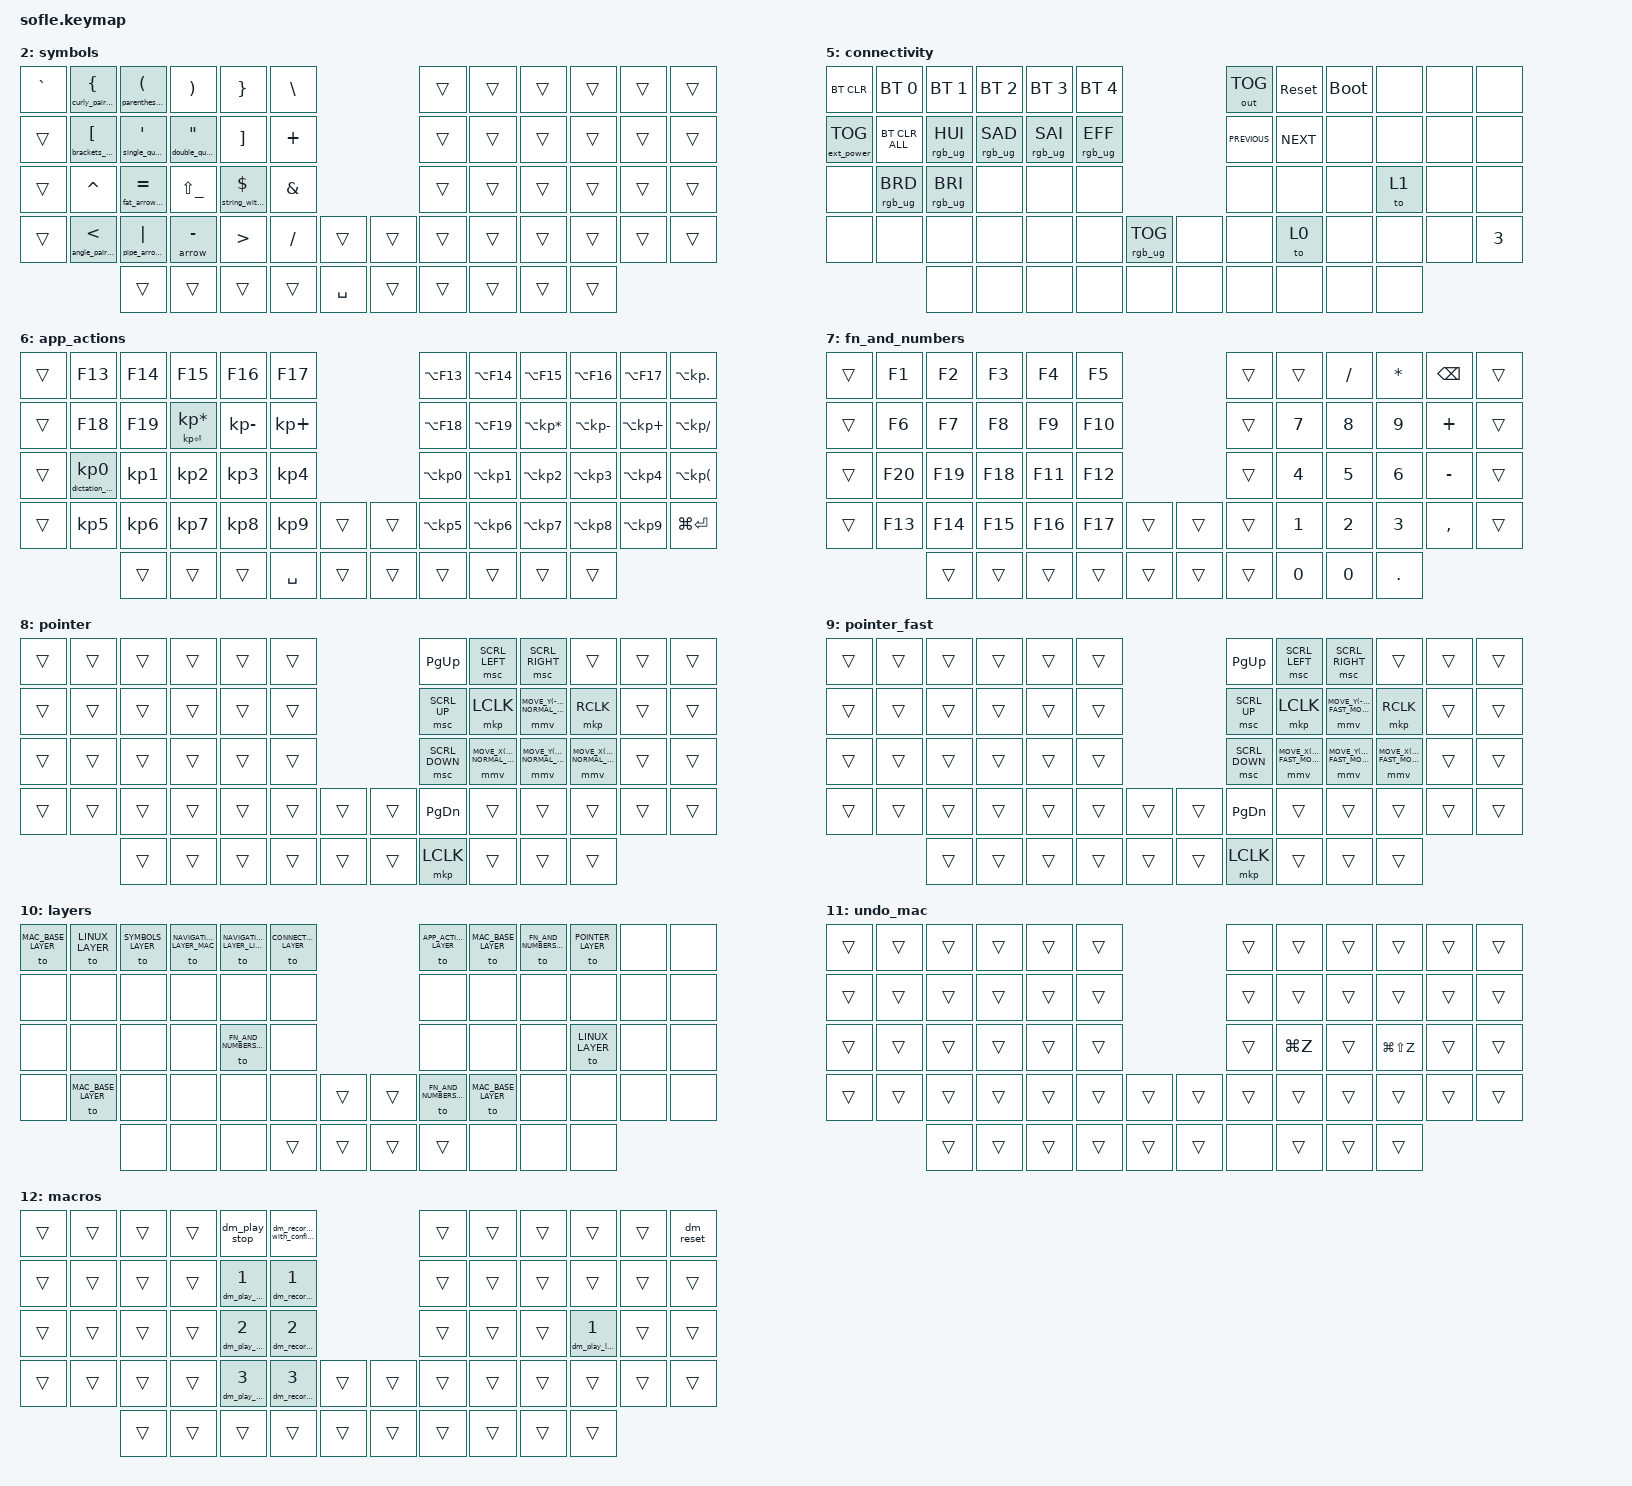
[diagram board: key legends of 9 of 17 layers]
/*
 * Copyright (c) 2020 The ZMK Contributors
 *
 * SPDX-License-Identifier: MIT
 */

#define ZMK_POINTING_DEFAULT_MOVE_VAL 1000  // default: 600
#define ZMK_POINTING_DEFAULT_SCRL_VAL 10    // default: 10
#define ZMK_POINTING_SLOW_MOVE_VAL 500
#define ZMK_POINTING_NORMAL_MOVE_VAL 1000
#define ZMK_POINTING_FAST_MOVE_VAL 3000

#include <behaviors.dtsi>
#include <dt-bindings/zmk/bt.h>
#include <dt-bindings/zmk/ext_power.h>
#include <dt-bindings/zmk/keys.h>
#include <dt-bindings/zmk/outputs.h>
#include <dt-bindings/zmk/pointing.h>
#include <dt-bindings/zmk/rgb.h>

#define OUTPUT_SOURCE_KEYCODE_STATE_CHANGE 3
#define MAC_BASE_LAYER 0
#define LINUX_LAYER 1
#define SYMBOLS_LAYER 2
#define NAVIGATION_LAYER_MAC 3
#define NAVIGATION_LAYER_LINUX 4
#define CONNECTIVITY_LAYER 5
#define APP_ACTIONS_LAYER 6
#define FN_AND_NUMBERS_LAYER 7
#define POINTER_LAYER 8
#define POINTER_FAST_LAYER 9
#define LAYERS_LAYER 10
#define UNDO_MAC_LAYER 11
#define MACROS_LAYER 12
#define APP_SWITCH_LAYER_LNX 13
#define WINDOW_SWITCH_LAYER_LNX 14
#define APP_SWITCH_LAYER_MAC 15
#define WINDOW_SWITCH_LAYER_MAC 16
#define SWITCH_COMBOS_TIMEOUT_MS 70
#define SWITCH_COMBOS_REQUIRE_PRIOR_IDLE_MS 400
#define STAGED_HOLD_TIMEOUT_MS 2000
#define STAGED_HOLD_WORD_STEP_MS 100

&left_encoder { status = "disabled"; };

&right_encoder {
    status = "ok";
    steps = <60>;
};

&sensors { triggers-per-rotation = <30>; };

/ {
    behaviors {
        backspace_words_mac: backspace_words_mac {
            compatible = "zmk,behavior-interval-repeat";
            #binding-cells = <0>;
            interval-ms = <STAGED_HOLD_WORD_STEP_MS>;
            bindings = <&kp LA(BACKSPACE)>;
        };

        backspace_staged_hold_mac: backspace_staged_hold_mac {
            compatible = "zmk,behavior-staged-hold";
            #binding-cells = <0>;
            timeout-ms = <STAGED_HOLD_TIMEOUT_MS>;
            on-press-bindings = <&kp BACKSPACE>;
            after-timeout-bindings = <&backspace_words_mac>;
        };

        left_staged_hold_mac: left_staged_hold_mac {
            compatible = "zmk,behavior-staged-hold";
            #binding-cells = <0>;
            timeout-ms = <STAGED_HOLD_TIMEOUT_MS>;
            on-press-bindings = <&kp LEFT>;
            after-timeout-bindings = <&kp LA(LEFT)>;
        };

        right_staged_hold_mac: right_staged_hold_mac {
            compatible = "zmk,behavior-staged-hold";
            #binding-cells = <0>;
            timeout-ms = <STAGED_HOLD_TIMEOUT_MS>;
            on-press-bindings = <&kp RIGHT>;
            after-timeout-bindings = <&kp LA(RIGHT)>;
        };

        backspace_words_lnx: backspace_words_lnx {
            compatible = "zmk,behavior-interval-repeat";
            #binding-cells = <0>;
            interval-ms = <STAGED_HOLD_WORD_STEP_MS>;
            bindings = <&kp LC(BACKSPACE)>;
        };

        backspace_staged_hold_lnx: backspace_staged_hold_lnx {
            compatible = "zmk,behavior-staged-hold";
            #binding-cells = <0>;
            timeout-ms = <STAGED_HOLD_TIMEOUT_MS>;
            on-press-bindings = <&kp BACKSPACE>;
            after-timeout-bindings = <&backspace_words_lnx>;
        };

        left_words_lnx: left_words_lnx {
            compatible = "zmk,behavior-interval-repeat";
            #binding-cells = <0>;
            interval-ms = <STAGED_HOLD_WORD_STEP_MS>;
            bindings = <&kp LC(LEFT)>;
        };

        left_staged_hold_lnx: left_staged_hold_lnx {
            compatible = "zmk,behavior-staged-hold";
            #binding-cells = <0>;
            timeout-ms = <STAGED_HOLD_TIMEOUT_MS>;
            on-press-bindings = <&kp LEFT>;
            after-timeout-bindings = <&left_words_lnx>;
        };

        right_words_lnx: right_words_lnx {
            compatible = "zmk,behavior-interval-repeat";
            #binding-cells = <0>;
            interval-ms = <STAGED_HOLD_WORD_STEP_MS>;
            bindings = <&kp LC(RIGHT)>;
        };

        right_staged_hold_lnx: right_staged_hold_lnx {
            compatible = "zmk,behavior-staged-hold";
            #binding-cells = <0>;
            timeout-ms = <STAGED_HOLD_TIMEOUT_MS>;
            on-press-bindings = <&kp RIGHT>;
            after-timeout-bindings = <&right_words_lnx>;
        };

        double_space_to_enter: double_space_to_enter {
            compatible = "zmk,behavior-tap-dance";
            #binding-cells = <0>;
            bindings = <&lt SYMBOLS_LAYER SPACE>, <&kp ENTER>;
        };

        gresc_ctrl: gresc_ctrl {
            compatible = "zmk,behavior-mod-morph";
            bindings = <&kp ESCAPE>, <&kp GRAVE>;

            #binding-cells = <0>;
            mods = <(MOD_LCTL|MOD_LGUI|MOD_LSFT|MOD_LALT)>;
        };

        dot_arrow: dot_arrow {
            compatible = "zmk,behavior-hold-tap";
            bindings = <&arrow>, <&kp>;

            #binding-cells = <2>;
            tapping-term-ms = <200>;
            flavor = "tap-preferred";
        };

        delayed_tap_hold_one: delayed_tap_hold_one {
            compatible = "zmk,behavior-hold-tap";
            bindings = <&kp>, <&kp>;

            #binding-cells = <2>;
            tapping-term-ms = <300>;
            flavor = "tap-preferred";
            require-prior-idle-ms = <200>;
        };

        hold_on_tab_mt: hold_on_tab_mt {
            compatible = "zmk,behavior-hold-tap";
            bindings = <&mt>, <&kp>;

            #binding-cells = <2>;
            tapping-term-ms = <400>;
            flavor = "tap-preferred";
        };

        shift_caps: shift_caps {
            compatible = "zmk,behavior-tap-dance";
            #binding-cells = <0>;
            bindings = <&kp LEFT_SHIFT>, <&kp CAPSLOCK>;
        };

        only_hold: only_hold {
            compatible = "zmk,behavior-hold-tap";
            bindings = <&kp>, <&none>;

            #binding-cells = <2>;
            tapping-term-ms = <400>;
            flavor = "tap-preferred";
        };

        only_tap_none_hold: only_tap_none_hold {
            compatible = "zmk,behavior-hold-tap";
            bindings = <&none>, <&kp>;

            #binding-cells = <2>;
            tapping-term-ms = <200>;
        };

        paste_on_hold_once: paste_on_hold_once {
            compatible = "zmk,behavior-hold-tap";
            bindings = <&paste_once>, <&kp>;

            #binding-cells = <2>;
            flavor = "tap-preferred";
            tapping-term-ms = <150>;
        };

        monosnap_image_copy: monosnap_image_copy {
            compatible = "zmk,behavior-mod-morph";
            bindings = <&kp C>, <&kp LA(LG(C))>;

            #binding-cells = <0>;
            mods = <(MOD_LCTL|MOD_LGUI)>;
        };

        copy_stuff: copy_stuff {
            compatible = "zmk,behavior-hold-tap";
            bindings = <&kp>, <&monosnap_image_copy>;

            #binding-cells = <2>;
            tapping-term-ms = <400>;
            flavor = "tap-preferred";
        };

        enter_shift_enter: enter_shift_enter {
            compatible = "zmk,behavior-hold-tap";
            bindings = <&single_shift_enter>, <&kp>;

            #binding-cells = <2>;
            tapping-term-ms = <200>;
            flavor = "tap-preferred";
        };

        to_layer_on_hold: to_layer_on_hold {
            compatible = "zmk,behavior-hold-tap";
            bindings = <&to>, <&kp>;

            #binding-cells = <2>;
            flavor = "tap-preferred";
            tapping-term-ms = <1000>;
        };

        copy_once_on_hold: copy_once_on_hold {
            compatible = "zmk,behavior-mod-morph";
            bindings = <&copy_once_on_hold_inner 0 C>, <&kp C>;

            #binding-cells = <0>;
            mods = <(MOD_LCTL|MOD_LGUI|MOD_LSFT|MOD_LALT)>;
            keep-mods = <(MOD_LCTL|MOD_LGUI|MOD_LSFT|MOD_LALT)>;
        };

        copy_once_on_hold_inner: copy_once_on_hold_inner {
            compatible = "zmk,behavior-hold-tap";
            bindings = <&copy_once>, <&kp>;

            #binding-cells = <2>;
            flavor = "tap-preferred";
            tapping-term-ms = <150>;
        };

        copy_once_on_hold_lnx: copy_once_on_hold_lnx {
            compatible = "zmk,behavior-mod-morph";
            bindings = <&copy_once_on_hold_inner_lnx 0 C>, <&kp C>;

            #binding-cells = <0>;
            mods = <(MOD_LCTL|MOD_LGUI|MOD_LSFT|MOD_LALT)>;
            keep-mods = <(MOD_LCTL|MOD_LGUI|MOD_LSFT|MOD_LALT)>;
        };

        copy_once_on_hold_inner_lnx: copy_once_on_hold_inner_lnx {
            compatible = "zmk,behavior-hold-tap";
            bindings = <&copy_once_lnx>, <&kp>;

            #binding-cells = <2>;
            flavor = "tap-preferred";
            tapping-term-ms = <150>;
        };

        ctrl_esc: ctrl_esc {
            compatible = "zmk,behavior-mod-morph";
            bindings = <&shift_esc>, <&kp LC(GRAVE)>;

            #binding-cells = <0>;
            mods = <(MOD_LCTL)>;
        };

        shift_esc: shift_esc {
            compatible = "zmk,behavior-mod-morph";
            bindings = <&esc_double_on_hold 0 0>, <&kp TILDE>;

            #binding-cells = <0>;
            mods = <(MOD_LSFT)>;
        };

        esc_double_on_hold: esc_double_on_hold {
            compatible = "zmk,behavior-hold-tap";
            bindings = <&esc_double_macro>, <&esc_tapdance>;

            #binding-cells = <2>;
            tapping-term-ms = <500>;
            flavor = "tap-preferred";
        };

        esc_tapdance: esc_tapdance {
            compatible = "zmk,behavior-tap-dance";
            #binding-cells = <0>;
            bindings =
                <&kp ESCAPE>,
                <&backtick_wrap>,
                <&triple_backtick>,
                <&triple_backtick_wrap_macro>;

            tapping-term-ms = <300>;
        };

        undo_once_on_hold: undo_once_on_hold {
            compatible = "zmk,behavior-hold-tap";
            bindings = <&undo_once>, <&kp>;

            #binding-cells = <2>;
            flavor = "tap-preferred";
            tapping-term-ms = <150>;
        };

        cut_once_on_hold: cut_once_on_hold {
            compatible = "zmk,behavior-hold-tap";
            bindings = <&cut_once>, <&kp>;

            #binding-cells = <2>;
            flavor = "tap-preferred";
            tapping-term-ms = <150>;
        };

        caps_lock_once_on_hold: caps_lock_once_on_hold {
            compatible = "zmk,behavior-hold-tap";
            bindings = <&caps_lock_once>, <&kp>;

            #binding-cells = <2>;
            flavor = "tap-preferred";
            tapping-term-ms = <200>;
        };

        paste_link_on_hold_once: paste_link_on_hold_once {
            compatible = "zmk,behavior-hold-tap";
            bindings = <&paste_link_macro>, <&kp>;

            #binding-cells = <2>;
            flavor = "tap-preferred";
            tapping-term-ms = <300>;
        };

        insert_bookmark_on_hold_once: insert_bookmark_on_hold_once {
            compatible = "zmk,behavior-hold-tap";
            bindings = <&insert_bookmark_macro>, <&kp>;

            #binding-cells = <2>;
            flavor = "tap-preferred";
            tapping-term-ms = <300>;
        };

        delayed_tap_once_on_hold: delayed_tap_once_on_hold {
            compatible = "zmk,behavior-hold-tap";
            bindings = <&key_once_macro>, <&kp>;

            #binding-cells = <2>;
            tapping-term-ms = <200>;
            flavor = "tap-preferred";
        };

        delayed_tap_once_haptic_on_hold: delayed_tap_once_haptic_on_hold {
            compatible = "zmk,behavior-hold-tap";
            bindings = <&key_once_haptic_macro>, <&kp>;

            #binding-cells = <2>;
            tapping-term-ms = <250>;
            flavor = "tap-preferred";
        };

        delayed_tap_once_haptic_on_hold_short: delayed_tap_once_haptic_on_hold_short {
            compatible = "zmk,behavior-hold-tap";
            bindings = <&key_once_haptic_macro>, <&kp>;

            #binding-cells = <2>;
            tapping-term-ms = <150>;
            flavor = "tap-preferred";
        };

        delayed_tap_once_haptic_on_hold_right: delayed_tap_once_haptic_on_hold_right {
            compatible = "zmk,behavior-hold-tap";
            bindings = <&key_once_haptic_macro_right>, <&kp>;

            #binding-cells = <2>;
            tapping-term-ms = <250>;
            flavor = "tap-preferred";
        };

        parenthesis_pair_on_hold: parenthesis_pair_on_hold {
            compatible = "zmk,behavior-hold-tap";
            bindings = <&parenthesis_pair_macro>, <&kp>;

            #binding-cells = <2>;
            tapping-term-ms = <200>;
            flavor = "tap-preferred";
        };

        brackets_pair_on_hold: brackets_pair_on_hold {
            compatible = "zmk,behavior-hold-tap";
            bindings = <&brackets_pair_macro>, <&kp>;

            #binding-cells = <2>;
            tapping-term-ms = <200>;
            flavor = "tap-preferred";
        };

        angle_pair_on_hold: angle_pair_on_hold {
            compatible = "zmk,behavior-hold-tap";
            bindings = <&angle_pair_macro>, <&kp>;

            #binding-cells = <2>;
            tapping-term-ms = <200>;
            flavor = "tap-preferred";
        };

        curly_pair_on_hold: curly_pair_on_hold {
            compatible = "zmk,behavior-hold-tap";
            bindings = <&curly_pair_macro>, <&kp>;

            #binding-cells = <2>;
            tapping-term-ms = <200>;
            flavor = "tap-preferred";
        };

        double_quote_pair_on_hold: double_quote_pair_on_hold {
            compatible = "zmk,behavior-hold-tap";
            bindings = <&double_quote_pair_macro>, <&kp>;

            #binding-cells = <2>;
            tapping-term-ms = <200>;
            flavor = "tap-preferred";
        };

        control_tapdance_to_suggestion: control_tapdance_to_suggestion {
            compatible = "zmk,behavior-tap-dance";
            label = "CONTROL_TAPDANCE_TO_SUGGESTION";
            #binding-cells = <0>;
            bindings = <&kp LCTRL>, <&kp LC(SPACE)>;

            tapping-term-ms = <250>;
        };

        long_delayed_tap_once_on_hold: long_delayed_tap_once_on_hold {
            compatible = "zmk,behavior-hold-tap";
            bindings = <&key_once_macro>, <&kp>;

            #binding-cells = <2>;
            tapping-term-ms = <500>;
            flavor = "tap-preferred";
            label = "LONG_DELAYED_TAP_ONCE_ON_HOLD";
        };

        fat_arrow_on_hold: fat_arrow_on_hold {
            compatible = "zmk,behavior-hold-tap";
            bindings = <&fat_arrow_macro>, <&kp>;

            #binding-cells = <2>;
            tapping-term-ms = <200>;
            flavor = "tap-preferred";
            label = "FAT_ARROW_ON_HOLD";
        };

        pipe_arrow_on_hold: pipe_arrow_on_hold {
            compatible = "zmk,behavior-hold-tap";
            bindings = <&pipe_arrow_macro>, <&kp>;

            #binding-cells = <2>;
            tapping-term-ms = <200>;
            flavor = "tap-preferred";
            label = "PIPE_ARROW_ON_HOLD";
        };

        string_with_var_on_hold: string_with_var_on_hold {
            compatible = "zmk,behavior-hold-tap";
            bindings = <&string_with_var_macro>, <&kp>;

            #binding-cells = <2>;
            tapping-term-ms = <200>;
            flavor = "tap-preferred";
            label = "STRING_WITH_VAR_ON_HOLD";
        };

        single_quote_pair_on_hold: single_quote_pair_on_hold {
            compatible = "zmk,behavior-hold-tap";
            bindings = <&single_quote_pair_macro>, <&kp>;

            #binding-cells = <2>;
            tapping-term-ms = <200>;
            flavor = "tap-preferred";
            label = "SINGLE_QUOTE_PAIR_ON_HOLD";
        };

        dictation_change_mode: dictation_change_mode {
            compatible = "zmk,behavior-mod-morph";
            label = "DICTATION_CHANGE_MODE";
            bindings =
                <&dictation_tap_hold LA(SPACE) LA(SPACE)>,
                <&kp LA(LG(SPACE))>;

            #binding-cells = <0>;
            mods = <(MOD_LGUI)>;
        };

        dictation_tap_hold: dictation_tap_hold {
            compatible = "zmk,behavior-hold-tap";
            bindings = <&dictation_alt_toggle_macro>, <&kp>;

            #binding-cells = <2>;
            tapping-term-ms = <200>;
            flavor = "tap-preferred";
        };

        dm_record: dm_record {
            compatible = "zmk,behavior-dm-record";
            #binding-cells = <1>;
        };

        dm_play: dm_play {
            compatible = "zmk,behavior-dm-play";
            #binding-cells = <1>;
        };

        dm_play_loop: dm_play_loop {
            compatible = "zmk,behavior-dm-play-loop";
            #binding-cells = <1>;
        };

        dm_record_stop: dm_record_stop {
            compatible = "zmk,behavior-dm-record-stop";
            #binding-cells = <0>;
        };

        dm_play_stop: dm_play_stop {
            compatible = "zmk,behavior-dm-play-stop";
            #binding-cells = <0>;
        };

        dm_reset: dm_reset {
            compatible = "zmk,behavior-dm-reset";
            #binding-cells = <0>;
        };

        dictation_home_row_on_hold: dictation_home_row_on_hold {
            compatible = "zmk,behavior-hold-tap";
            bindings = <&dictation_home_row>, <&kp>;

            #binding-cells = <2>;
            tapping-term-ms = <400>;
            flavor = "tap-preferred";
        };
    };

    macros {
        arrow: arrow {
            compatible = "zmk,behavior-macro";
            #binding-cells = <0>;
            bindings = <&kp MINUS &kp GT &kp LC(SPACE)>;
        };

        esc_double_macro: esc_double_macro {
            compatible = "zmk,behavior-macro";
            #binding-cells = <0>;
            bindings = <&kp ESCAPE &kp ESCAPE &haptic_long_press>;
        };

        paste_once: paste_plain {
            compatible = "zmk,behavior-macro";
            #binding-cells = <0>;
            bindings = <&kp LG(V) &haptic_long_press>;
        };

        single_shift_enter: single_shift_enter {
            compatible = "zmk,behavior-macro";
            #binding-cells = <0>;
            bindings = <&kp LS(ENTER)>;
        };

        copy_once: copy_once {
            compatible = "zmk,behavior-macro";
            #binding-cells = <0>;
            bindings = <&kp LG(C) &haptic_long_press>;
        };

        copy_once_lnx: copy_once_lnx {
            compatible = "zmk,behavior-macro";
            #binding-cells = <0>;
            bindings = <&kp LC(C) &haptic_long_press>;
        };

        triple_backtick: triple_backtick {
            compatible = "zmk,behavior-macro";
            #binding-cells = <0>;
            bindings = <&kp GRAVE &kp GRAVE &kp GRAVE>;
        };

        backtick_wrap: backtick_wrap {
            compatible = "zmk,behavior-macro";
            #binding-cells = <0>;
            bindings = <&kp LG(X) &kp GRAVE &kp GRAVE &kp LEFT_ARROW &kp LG(V)>;
        };

        undo_once: undo_once {
            compatible = "zmk,behavior-macro";
            #binding-cells = <0>;
            bindings =
                <&kp LG(Z) &haptic_long_press>,
                <&macro_press>,
                <&mo UNDO_MAC_LAYER>,
                <&macro_pause_for_release>,
                <&macro_release>,
                <&mo UNDO_MAC_LAYER>;
        };

        cut_once: cut_once {
            compatible = "zmk,behavior-macro";
            #binding-cells = <0>;
            bindings = <&kp LG(X) &haptic_long_press>;
        };

        caps_lock_once: caps_lock_once {
            compatible = "zmk,behavior-macro";
            #binding-cells = <0>;
            bindings = <&kp CAPSLOCK &haptic_long_press>;
        };

        paste_link_macro: paste_link_macro {
            compatible = "zmk,behavior-macro";
            #binding-cells = <0>;
            bindings =
                <&kp LG(K)>,
                <&macro_wait_time 200>,
                <&kp LG(V) &kp ENTER>;
        };

        insert_bookmark_macro: insert_bookmark {
            compatible = "zmk,behavior-macro";
            #binding-cells = <0>;
            bindings =
                <&kp LC(LA(I))>,
                <&macro_wait_time 200>,
                <&kp B &haptic_long_press>;
        };

        triple_backtick_wrap_macro: triple_backtick_wrap_macro {
            compatible = "zmk,behavior-macro";
            #binding-cells = <0>;
            bindings =
                <&kp GRAVE &kp GRAVE &kp GRAVE>,
                <&macro_wait_time 100>,
                <&kp LS(ENTER) &kp LG(V)>,
                <&macro_wait_time 15>,
                <&kp LS(ENTER) &kp GRAVE &kp GRAVE &kp GRAVE>;
        };

        docs_reset_format_macro: docs_reset_format_macro {
            compatible = "zmk,behavior-macro";
            #binding-cells = <0>;
            bindings = <&none>;
        };

        docs_wrap_text_macro: docs_wrap_text_macro {
            compatible = "zmk,behavior-macro";
            #binding-cells = <0>;
            bindings = <&kp LC(LA(O)) &kp W &kp W>;
        };

        key_once_macro: key_once_macro {
            compatible = "zmk,behavior-macro-one-param";
            #binding-cells = <1>;
            bindings = <&macro_param_1to1 &kp MACRO_PLACEHOLDER>;
        };

        key_once_haptic_macro: key_once_haptic_macro {
            compatible = "zmk,behavior-macro-one-param";
            #binding-cells = <1>;
            bindings = <&macro_param_1to1 &kp MACRO_PLACEHOLDER &haptic_long_press>;
        };

        key_once_haptic_macro_right: key_once_haptic_macro_right {
            compatible = "zmk,behavior-macro-one-param";
            #binding-cells = <1>;
            bindings = <&macro_param_1to1 &kp MACRO_PLACEHOLDER &haptic_long_press_right>;
        };

        parenthesis_pair_macro: parenthesis_pair_macro {
            compatible = "zmk,behavior-macro";
            #binding-cells = <0>;
            bindings = <&kp LPAR &kp RPAR &kp LEFT &haptic_long_press>;
        };

        brackets_pair_macro: brackets_pair_macro {
            compatible = "zmk,behavior-macro";
            #binding-cells = <0>;
            bindings = <&kp LEFT_BRACKET &kp RIGHT_BRACKET &kp LEFT &haptic_long_press>;
        };

        angle_pair_macro: angle_pair_macro {
            compatible = "zmk,behavior-macro";
            #binding-cells = <0>;
            bindings = <&kp LT &kp GT &kp LEFT &haptic_long_press>;
        };

        curly_pair_macro: curly_pair_macro {
            compatible = "zmk,behavior-macro";
            #binding-cells = <0>;
            bindings = <&kp LS(LBRC) &kp RBRC &kp LEFT &haptic_long_press>;
        };

        double_quote_pair_macro: double_quote_pair_macro {
            compatible = "zmk,behavior-macro";
            #binding-cells = <0>;
            bindings = <&kp DQT &kp DQT &kp LEFT &haptic_long_press>;
        };

        fat_arrow_macro: fat_arrow_macro {
            compatible = "zmk,behavior-macro";
            #binding-cells = <0>;
            bindings = <&kp KP_EQUAL &kp GREATER_THAN &haptic_long_press>;
            label = "FAT_ARROW_MACRO";
        };

        pipe_arrow_macro: pipe_arrow_macro {
            compatible = "zmk,behavior-macro";
            #binding-cells = <0>;
            bindings = <&kp PIPE &kp GREATER_THAN &haptic_long_press>;
            label = "PIPE_ARROW_MACRO";
        };

        string_with_var_macro: string_with_var_macro {
            compatible = "zmk,behavior-macro";
            #binding-cells = <0>;
            bindings = <&kp DOLLAR &kp LEFT_BRACE &kp RIGHT_BRACE &kp LEFT &haptic_long_press>;
            label = "STRING_WITH_VAR_MACRO";
        };

        single_quote_pair_macro: single_quote_pair_macro {
            compatible = "zmk,behavior-macro";
            #binding-cells = <0>;
            bindings = <&kp SQT &kp SQT &kp LEFT &haptic_long_press>;
            label = "SINGLE_QUOTE_PAIR_MACRO";
        };

        dictation_toggle_macro: dictation_toggle_macro {
            compatible = "zmk,behavior-macro";
            #binding-cells = <0>;
            bindings =
                <&kp LA(ESCAPE)>,
                <&macro_pause_for_release>,
                <&kp LA(ESCAPE)>;

            label = "DICTATION_TOGGLE_MACRO";
        };

        dictation_alt_toggle_macro: dictation_alt_toggle_macro {
            compatible = "zmk,behavior-macro";
            #binding-cells = <0>;
            bindings =
                <&kp LA(SPACE)>,
                <&macro_pause_for_release>,
                <&kp LA(SPACE)>;

            label = "DICTATION_ALT_TOGGLE_MACRO";
        };

        dm_record_with_confirmation: record_with_confirmation {
            compatible = "zmk,behavior-macro-one-param";
            #binding-cells = <1>;
            bindings = <&macro_param_1to1 &haptic_drv2605 MACRO_PLACEHOLDER &dm_record MACRO_PLACEHOLDER>;
        };

        dm_record_stop_with_confirmation: record_stop_with_confirmation {
            compatible = "zmk,behavior-macro";
            #binding-cells = <0>;
            bindings = <&dm_record_stop &haptic_drv2605 12>;
        };

        dm_play_with_confirmation: play_with_confirmation {
            compatible = "zmk,behavior-macro-one-param";
            #binding-cells = <1>;
            bindings =
                <&macro_param_1to1>,
                <&macro_wait_time 1000>,
                <&haptic_drv2605 MACRO_PLACEHOLDER &dm_play MACRO_PLACEHOLDER>;
        };

        dm_play_loop_with_confirmation: dm_play_loop_with_confirmation {
            compatible = "zmk,behavior-macro-one-param";
            #binding-cells = <1>;
            bindings =
                <&macro_param_1to1>,
                <&macro_wait_time 1000>,
                <&haptic_drv2605 MACRO_PLACEHOLDER &dm_play_loop MACRO_PLACEHOLDER>;
        };

        haptic_long_press: haptic_long_press {
            compatible = "zmk,behavior-macro";
            #binding-cells = <0>;
            bindings = <&haptic_drv2605 9>;
        };

        haptic_long_press_right: haptic_long_press_right {
            compatible = "zmk,behavior-macro";
            #binding-cells = <0>;
            bindings = <&haptic_drv2605_right 9>;
        };

        mouse_reset_position: mouse_reset_position {
            compatible = "zmk,behavior-macro";
            #binding-cells = <0>;
            bindings = <&mmv MOVE_Y(600) &mmv (MOVE_X(-600))>;
            label = "MOUSE_RESET_POSITION";
        };

        app_switch_start_lnx: app_switch_start_lnx {
            compatible = "zmk,behavior-macro";
            #binding-cells = <0>;
            bindings =
                <&macro_press>,
                <&mo APP_SWITCH_LAYER_LNX &kp LEFT_ALT>,
                <&macro_tap>,
                <&kp TAB>;
        };

        app_switch_start_mac: app_switch_start_mac {
            compatible = "zmk,behavior-macro";
            #binding-cells = <0>;
            bindings =
                <&macro_press>,
                <&mo APP_SWITCH_LAYER_MAC &kp LEFT_GUI>,
                <&macro_tap>,
                <&kp TAB>;
        };

        app_switch_confirm: app_switch_confirm {
            compatible = "zmk,behavior-macro";
            #binding-cells = <0>;
            bindings =
                <&macro_release>,
                <&kp LEFT_GUI &kp LEFT_ALT &mo APP_SWITCH_LAYER_MAC &mo APP_SWITCH_LAYER_LNX>,
                <&macro_tap>;
        };

        app_switch_cancel: app_switch_cancel {
            compatible = "zmk,behavior-macro";
            #binding-cells = <0>;
            bindings =
                <&macro_tap>,
                <&kp ESC>,
                <&macro_release>,
                <&kp LEFT_GUI &kp LEFT_ALT &mo APP_SWITCH_LAYER_MAC &mo APP_SWITCH_LAYER_LNX>;
        };

        window_switch_start_lnx: window_switch_start_lnx {
            compatible = "zmk,behavior-macro";
            #binding-cells = <0>;
            bindings =
                <&macro_press>,
                <&mo WINDOW_SWITCH_LAYER_LNX &kp LEFT_ALT>,
                <&macro_tap>,
                <&kp GRAVE>;
        };

        window_switch_start_mac: window_switch_start_mac {
            compatible = "zmk,behavior-macro";
            #binding-cells = <0>;
            bindings =
                <&macro_press>,
                <&mo WINDOW_SWITCH_LAYER_MAC &kp LEFT_ALT>,
                <&macro_tap>,
                <&kp GRAVE>;
        };

        window_switch_confirm: window_switch_confirm {
            compatible = "zmk,behavior-macro";
            #binding-cells = <0>;
            bindings =
                <&macro_release>,
                <&kp LEFT_ALT &mo WINDOW_SWITCH_LAYER_LNX &mo WINDOW_SWITCH_LAYER_MAC>,
                <&macro_tap>;
        };

        window_switch_cancel: window_switch_cancel {
            compatible = "zmk,behavior-macro";
            #binding-cells = <0>;
            bindings =
                <&macro_tap>,
                <&kp ESC>,
                <&macro_release>,
                <&kp LEFT_ALT &mo WINDOW_SWITCH_LAYER_LNX &mo WINDOW_SWITCH_LAYER_MAC>;
        };

        app_switch_to_window_switch_lnx: app_switch_to_window_switch_lnx {
            compatible = "zmk,behavior-macro";
            #binding-cells = <0>;
            bindings = <&app_switch_cancel &window_switch_start_lnx>;
        };

        app_switch_to_window_switch_mac: app_switch_to_window_switch_mac {
            compatible = "zmk,behavior-macro";
            #binding-cells = <0>;
            bindings = <&app_switch_cancel &window_switch_start_mac>;
        };

        window_switch_to_app_switch_lnx: window_switch_to_app_switch_lnx {
            compatible = "zmk,behavior-macro";
            #binding-cells = <0>;
            bindings = <&window_switch_cancel &app_switch_start_lnx>;
        };

        window_switch_to_app_switch_mac: window_switch_to_app_switch_mac {
            compatible = "zmk,behavior-macro";
            #binding-cells = <0>;
            bindings = <&window_switch_cancel &app_switch_start_mac>;
        };

        dictation_home_row: dictation_home_row {
            compatible = "zmk,behavior-macro";
            #binding-cells = <0>;
            bindings = <&kp LA(SPACE) &haptic_drv2605 13>;
        };
    };

    combos {
        compatible = "zmk,combos";

        to_pointer_layer {
            bindings = <&mo POINTER_LAYER>;
            key-positions = <28 27 26>;
            layers = <6>;
            timeout-ms = <1000>;
        };

        to_pointer_fast_layer {
            bindings = <&mo POINTER_FAST_LAYER>;
            key-positions = <16 14 15>;
            layers = <6>;
            timeout-ms = <1000>;
        };

        app_switch_lnx {
            bindings = <&app_switch_start_lnx>;
            key-positions = <28 27>;
            require-prior-idle-ms = <SWITCH_COMBOS_REQUIRE_PRIOR_IDLE_MS>;
            timeout-ms = <SWITCH_COMBOS_TIMEOUT_MS>;
            layers = <LINUX_LAYER>;
            slow-release;
        };

        app_switch_mac {
            bindings = <&app_switch_start_mac>;
            key-positions = <28 27>;
            require-prior-idle-ms = <SWITCH_COMBOS_REQUIRE_PRIOR_IDLE_MS>;
            timeout-ms = <SWITCH_COMBOS_TIMEOUT_MS>;
            layers = <MAC_BASE_LAYER>;
            slow-release;
        };

        app_switch_previous_fast_lnx {
            bindings = <&kp LA(TAB)>;
            key-positions = <26 27 28>;
            require-prior-idle-ms = <SWITCH_COMBOS_REQUIRE_PRIOR_IDLE_MS>;
            timeout-ms = <SWITCH_COMBOS_TIMEOUT_MS>;
            layers = <LINUX_LAYER>;
        };

        app_switch_previous_fast_mac {
            bindings = <&kp LG(TAB)>;
            key-positions = <26 27 28>;
            require-prior-idle-ms = <SWITCH_COMBOS_REQUIRE_PRIOR_IDLE_MS>;
            timeout-ms = <SWITCH_COMBOS_TIMEOUT_MS>;
            layers = <MAC_BASE_LAYER>;
        };

        app_switch_on_app_switch_layer_lnx {
            bindings = <&app_switch_cancel>;
            key-positions = <28 27>;
            require-prior-idle-ms = <SWITCH_COMBOS_REQUIRE_PRIOR_IDLE_MS>;
            timeout-ms = <SWITCH_COMBOS_TIMEOUT_MS>;
            layers = <APP_SWITCH_LAYER_LNX>;
            slow-release;
        };

        app_switch_on_app_switch_layer_mac {
            bindings = <&app_switch_cancel>;
            key-positions = <28 27>;
            require-prior-idle-ms = <SWITCH_COMBOS_REQUIRE_PRIOR_IDLE_MS>;
            timeout-ms = <SWITCH_COMBOS_TIMEOUT_MS>;
            layers = <APP_SWITCH_LAYER_MAC>;
            slow-release;
        };

        app_switch_on_window_switch_layer_lnx {
            bindings = <&window_switch_to_app_switch_lnx>;
            key-positions = <28 27>;
            require-prior-idle-ms = <SWITCH_COMBOS_REQUIRE_PRIOR_IDLE_MS>;
            timeout-ms = <SWITCH_COMBOS_TIMEOUT_MS>;
            layers = <WINDOW_SWITCH_LAYER_LNX>;
            slow-release;
        };

        app_switch_on_window_switch_layer_mac {
            bindings = <&window_switch_to_app_switch_mac>;
            key-positions = <28 27>;
            require-prior-idle-ms = <SWITCH_COMBOS_REQUIRE_PRIOR_IDLE_MS>;
            timeout-ms = <SWITCH_COMBOS_TIMEOUT_MS>;
            layers = <WINDOW_SWITCH_LAYER_MAC>;
            slow-release;
        };

        window_switch_lnx {
            bindings = <&window_switch_start_lnx>;
            key-positions = <15 28>;
            slow-release;
            require-prior-idle-ms = <SWITCH_COMBOS_REQUIRE_PRIOR_IDLE_MS>;
            timeout-ms = <SWITCH_COMBOS_TIMEOUT_MS>;
            layers = <LINUX_LAYER>;
        };

        window_switch_mac {
            bindings = <&window_switch_start_mac>;
            key-positions = <15 28>;
            slow-release;
            require-prior-idle-ms = <SWITCH_COMBOS_REQUIRE_PRIOR_IDLE_MS>;
            timeout-ms = <SWITCH_COMBOS_TIMEOUT_MS>;
            layers = <MAC_BASE_LAYER>;
        };

        window_switch_previous_fast_lnx {
            bindings = <&kp LA(GRAVE)>;
            key-positions = <14 15 16>;
            require-prior-idle-ms = <SWITCH_COMBOS_REQUIRE_PRIOR_IDLE_MS>;
            timeout-ms = <SWITCH_COMBOS_TIMEOUT_MS>;
            layers = <LINUX_LAYER>;
        };

        window_switch_previous_fast_mac {
            bindings = <&kp LA(GRAVE)>;
            key-positions = <14 15 16>;
            require-prior-idle-ms = <SWITCH_COMBOS_REQUIRE_PRIOR_IDLE_MS>;
            timeout-ms = <SWITCH_COMBOS_TIMEOUT_MS>;
            layers = <MAC_BASE_LAYER>;
        };

        window_switch_on_window_switch_layer_lnx {
            bindings = <&window_switch_cancel>;
            key-positions = <15 28>;
            require-prior-idle-ms = <SWITCH_COMBOS_REQUIRE_PRIOR_IDLE_MS>;
            timeout-ms = <SWITCH_COMBOS_TIMEOUT_MS>;
            layers = <WINDOW_SWITCH_LAYER_LNX>;
            slow-release;
        };

        window_switch_on_window_switch_layer_mac {
            bindings = <&window_switch_cancel>;
            key-positions = <15 28>;
            require-prior-idle-ms = <SWITCH_COMBOS_REQUIRE_PRIOR_IDLE_MS>;
            timeout-ms = <SWITCH_COMBOS_TIMEOUT_MS>;
            layers = <WINDOW_SWITCH_LAYER_MAC>;
            slow-release;
        };

        window_switch_on_app_switch_layer_lnx {
            bindings = <&app_switch_to_window_switch_lnx>;
            key-positions = <15 28>;
            require-prior-idle-ms = <SWITCH_COMBOS_REQUIRE_PRIOR_IDLE_MS>;
            timeout-ms = <SWITCH_COMBOS_TIMEOUT_MS>;
            layers = <APP_SWITCH_LAYER_LNX>;
            slow-release;
        };

        window_switch_on_app_switch_layer_mac {
            bindings = <&app_switch_to_window_switch_mac>;
            key-positions = <15 28>;
            require-prior-idle-ms = <SWITCH_COMBOS_REQUIRE_PRIOR_IDLE_MS>;
            timeout-ms = <SWITCH_COMBOS_TIMEOUT_MS>;
            layers = <APP_SWITCH_LAYER_MAC>;
            slow-release;
        };
    };

    keymap {
        compatible = "zmk,keymap";

        mac {
            display-name = "mac";
            bindings = <
&ctrl_esc                        &delayed_tap_once_on_hold F1 N1           &delayed_tap_once_on_hold F2 N2           &delayed_tap_once_on_hold F3 N3    &delayed_tap_once_on_hold F4 N4           &delayed_tap_once_on_hold F5 N5                                                                 &delayed_tap_once_on_hold F6 N6               &delayed_tap_once_on_hold F7 N7    &delayed_tap_once_on_hold F8 N8  &delayed_tap_once_on_hold F9 N9                     &delayed_tap_once_on_hold F10 N0  &backspace_staged_hold_mac
&caps_lock_once_on_hold 0 TAB    &delayed_tap_hold_one LC(LA(Q)) Q         &delayed_tap_hold_one LS(LA(W)) W         &delayed_tap_hold_one LA(LS(E)) E  &delayed_tap_hold_one LA(LS(R)) R         &delayed_tap_hold_one LG(LC(T)) T                                                               &delayed_tap_hold_one LA(Y) Y                 &kp U                              &delayed_tap_hold_one LG(I) I    &delayed_tap_once_haptic_on_hold_right LA(LS(O)) O  &delayed_tap_once_on_hold F11 P   &delayed_tap_once_on_hold F12 LEFT_BRACKET
&kp LEFT_SHIFT                   &delayed_tap_once_haptic_on_hold LG(A) A  &delayed_tap_once_haptic_on_hold LG(S) S  &delayed_tap_hold_one LA(LS(D)) D  &delayed_tap_once_haptic_on_hold LG(F) F  &delayed_tap_hold_one LS(LA(G)) G                                                               &delayed_tap_once_haptic_on_hold LC(LG(H)) H  &kp J                              &kp K                            &delayed_tap_once_haptic_on_hold_right LS(LA(S)) L  &kp SEMI                          &kp SQT
&control_tapdance_to_suggestion  &undo_once_on_hold 0 Z                    &cut_once_on_hold 0 X                     &copy_once_on_hold                 &paste_on_hold_once 0 V                   &delayed_tap_hold_one LA(LS(B)) B  &lt (MACROS_LAYER) LC(LG(H))    &kp LC(LA(LG(F13)))          &kp N                                         &delayed_tap_hold_one LS(LA(M)) M  &kp COMMA                        &dot_arrow 0 DOT                                    &kp FSLH                          &kp ENTER
                                                                           &dictation_change_mode                    &kp LALT                           &kp LEFT_GUI                              &lt SYMBOLS_LAYER SPACE            &lt APP_ACTIONS_LAYER SPACE     &lt APP_ACTIONS_LAYER SPACE  &lt NAVIGATION_LAYER_MAC SPACE                &mo POINTER_LAYER                  &mo CONNECTIVITY_LAYER           &dictation_change_mode
            >;

            sensor-bindings =
                <&inc_dec_kp A B>,
                <&inc_dec_kp LG(LA(F14)) LG(LA(F13))>;
        };

        linux {
            display-name = "linux";
            bindings = <
&trans  &trans                                    &trans                                    &trans                  &trans                                    &trans                                          &trans                            &trans  &trans  &trans  &trans  &backspace_staged_hold_lnx
&trans  &trans                                    &trans                                    &trans                  &trans                                    &trans                                          &trans                            &trans  &trans  &trans  &trans  &trans
&trans  &delayed_tap_once_haptic_on_hold LC(A) A  &delayed_tap_once_haptic_on_hold LC(S) S  &trans                  &delayed_tap_once_haptic_on_hold LC(F) F  &trans                                          &trans                            &trans  &trans  &trans  &trans  &trans
&trans  &delayed_tap_once_haptic_on_hold LC(Z) Z  &delayed_tap_once_haptic_on_hold LC(X) X  &copy_once_on_hold_lnx  &delayed_tap_once_haptic_on_hold LC(V) V  &trans  &lt (MACROS_LAYER) LC(LA(H))    &none   &trans                            &trans  &trans  &trans  &trans  &trans
                                                  &trans                                    &kp LGUI                &kp LALT                                  &trans  &trans                          &trans  &lt NAVIGATION_LAYER_LINUX SPACE  &trans  &trans  &trans
            >;

            sensor-bindings = <&inc_dec_kp A Z>, <&inc_dec_kp DOWN UP>;
        };

        symbols {
            display-name = "symbols";
            bindings = <
&kp GRAVE  &curly_pair_on_hold 0 LEFT_BRACE       &parenthesis_pair_on_hold 0 LPAR  &kp RPAR                          &kp RIGHT_BRACE                    &kp BSLH                        &trans  &trans  &trans  &trans  &trans  &trans
&trans     &brackets_pair_on_hold 0 LEFT_BRACKET  &single_quote_pair_on_hold 0 SQT  &double_quote_pair_on_hold 0 DQT  &kp RIGHT_BRACKET                  &kp PLUS                        &trans  &trans  &trans  &trans  &trans  &trans
&trans     &kp CARET                              &fat_arrow_on_hold 0 EQUAL        &kp LS(UNDER)                     &string_with_var_on_hold 0 DOLLAR  &kp AMPS                        &trans  &trans  &trans  &trans  &trans  &trans
&trans     &angle_pair_on_hold 0 LT               &pipe_arrow_on_hold 0 PIPE        &dot_arrow 0 MINUS                &kp GT                             &kp SLASH  &trans       &trans  &trans  &trans  &trans  &trans  &trans  &trans
                                                  &trans                            &trans                            &trans                             &trans     &kp SPACE    &trans  &trans  &trans  &trans  &trans
            >;

            sensor-bindings = <&inc_dec_kp A B>, <&inc_dec_kp BACKSPACE SPACE>;
        };

        navigation_mac {
            display-name = "navigation_mac";
            bindings = <
&trans  &trans  &trans  &trans  &trans  &trans                    &kp PG_UP  &kp LG(UP_ARROW)       &kp LA(UP)             &trans                  &trans   &kp LA(BACKSPACE)
&trans  &trans  &trans  &trans  &trans  &trans                    &kp PG_DN  &kp LA(LEFT)           &kp UP                 &kp LA(RIGHT)           &trans   &trans
&trans  &trans  &trans  &trans  &trans  &trans                    &kp HOME   &left_staged_hold_mac  &kp DOWN               &right_staged_hold_mac  &kp END  &trans
&trans  &trans  &trans  &trans  &trans  &trans  &trans    &trans  &trans     &kp LG(DOWN_ARROW)     &kp LS(LG(LC(RIGHT)))  &trans                  &trans   &kp LS(ENTER)
                &trans  &trans  &trans  &trans  &trans    &trans  &trans     &trans                 &trans                 &trans
            >;

            sensor-bindings = <&inc_dec_kp A Z>, <&inc_dec_kp RIGHT LEFT>;
        };

        navigation_lnx {
            display-name = "navigation_lnx";
            bindings = <
&trans  &trans  &trans  &trans  &trans  &trans                    &kp PG_UP  &kp LG(UP_ARROW)       &kp LA(UP)             &trans                  &trans   &kp LC(BACKSPACE)
&trans  &trans  &trans  &trans  &trans  &trans                    &kp PG_DN  &kp LA(LEFT)           &kp UP                 &kp LA(RIGHT)           &trans   &trans
&trans  &trans  &trans  &trans  &trans  &trans                    &kp HOME   &left_staged_hold_lnx  &kp DOWN               &right_staged_hold_lnx  &kp END  &trans
&trans  &trans  &trans  &trans  &trans  &trans  &trans    &trans  &trans     &kp LG(DOWN_ARROW)     &kp LS(LG(LC(RIGHT)))  &trans                  &trans   &kp LS(ENTER)
                &trans  &trans  &trans  &trans  &trans    &trans  &trans     &trans                 &trans                 &trans
            >;

            sensor-bindings = <&inc_dec_kp A Z>, <&inc_dec_kp RIGHT LEFT>;
        };

        connectivity {
            display-name = "connectivity";
            bindings = <
&bt BT_CLR         &bt BT_SEL 0     &bt BT_SEL 1     &bt BT_SEL 2     &bt BT_SEL 3     &bt BT_SEL 4                               &out OUT_TOG    &sys_reset  &bootloader  &none  &none  &none
&ext_power EP_TOG  &bt BT_CLR_ALL   &rgb_ug RGB_HUI  &rgb_ug RGB_SAD  &rgb_ug RGB_SAI  &rgb_ug RGB_EFF                            &kp C_PREVIOUS  &kp C_NEXT  &none        &none  &none  &none
&none              &rgb_ug RGB_BRD  &rgb_ug RGB_BRI  &none            &none            &none                                      &none           &none       &none        &to 1  &none  &none
&none              &none            &none            &none            &none            &none            &rgb_ug RGB_TOG    &none  &none           &to 0       &none        &none  &none  &kp N3
                                    &none            &none            &none            &none            &none              &none  &none           &none       &none        &none
            >;
        };

        app_actions {
            bindings = <
&trans  &kp F13                              &kp F14    &kp F15                                                      &kp F16       &kp F17                        &kp LA(F13)    &kp LA(F14)    &kp LA(F15)          &kp LA(F16)       &kp LA(F17)      &kp LA(KP_DOT)
&trans  &kp F18                              &kp F19    &delayed_tap_once_haptic_on_hold_short KP_ENTER KP_MULTIPLY  &kp KP_MINUS  &kp KP_PLUS                    &kp LA(F18)    &kp LA(F19)    &kp LA(KP_MULTIPLY)  &kp LA(KP_MINUS)  &kp LA(KP_PLUS)  &kp LA(KP_DIVIDE)
&trans  &dictation_home_row_on_hold 0 KP_N0  &kp KP_N1  &kp KP_N2                                                    &kp KP_N3     &kp KP_N4                      &kp LA(KP_N0)  &kp LA(KP_N1)  &kp LA(KP_N2)        &kp LA(KP_N3)     &kp LA(KP_N4)    &kp LA(KP_LPAR)
&trans  &kp KP_N5                            &kp KP_N6  &kp KP_N7                                                    &kp KP_N8     &kp KP_N9    &trans    &trans  &kp LA(KP_N5)  &kp LA(KP_N6)  &kp LA(KP_N7)        &kp LA(KP_N8)     &kp LA(KP_N9)    &kp LG(ENTER)
                                             &trans     &trans                                                       &trans        &kp SPACE    &trans    &trans  &trans         &trans         &trans               &trans
            >;

            sensor-bindings = <&inc_dec_kp A Z>, <&inc_dec_kp LA(F18) LA(F19)>;
        };

        fn_and_numbers {
            bindings = <
&trans  &kp F1   &kp F2   &kp F3   &kp F4   &kp F5                     &trans  &trans        &kp FSLH      &kp ASTERISK  &kp BSPC   &trans
&trans  &kp F6   &kp F7   &kp F8   &kp F9   &kp F10                    &trans  &kp N7        &kp N8        &kp N9        &kp PLUS   &trans
&trans  &kp F20  &kp F19  &kp F18  &kp F11  &kp F12                    &trans  &kp N4        &kp N5        &kp N6        &kp MINUS  &trans
&trans  &kp F13  &kp F14  &kp F15  &kp F16  &kp F17  &trans    &trans  &trans  &kp NUMBER_1  &kp N2        &kp NUMBER_3  &kp COMMA  &trans
                 &trans   &trans   &trans   &trans   &trans    &trans  &trans  &kp N0        &kp NUMBER_0  &kp DOT
            >;
        };

        pointer {
            bindings = <
&trans  &trans  &trans  &trans  &trans  &trans                    &kp PAGE_UP     &msc SCRL_LEFT                              &msc SCRL_RIGHT                             &trans                                     &trans  &trans
&trans  &trans  &trans  &trans  &trans  &trans                    &msc SCRL_UP    &mkp LCLK                                   &mmv MOVE_Y(-ZMK_POINTING_NORMAL_MOVE_VAL)  &mkp RCLK                                  &trans  &trans
&trans  &trans  &trans  &trans  &trans  &trans                    &msc SCRL_DOWN  &mmv MOVE_X(-ZMK_POINTING_NORMAL_MOVE_VAL)  &mmv MOVE_Y(ZMK_POINTING_NORMAL_MOVE_VAL)   &mmv MOVE_X(ZMK_POINTING_NORMAL_MOVE_VAL)  &trans  &trans
&trans  &trans  &trans  &trans  &trans  &trans  &trans    &trans  &kp PAGE_DOWN   &trans                                      &trans                                      &trans                                     &trans  &trans
                &trans  &trans  &trans  &trans  &trans    &trans  &mkp LCLK       &trans                                      &trans                                      &trans
            >;
        };

        pointer_fast {
            bindings = <
&trans  &trans  &trans  &trans  &trans  &trans                    &kp PAGE_UP     &msc SCRL_LEFT                            &msc SCRL_RIGHT                           &trans                                   &trans  &trans
&trans  &trans  &trans  &trans  &trans  &trans                    &msc SCRL_UP    &mkp LCLK                                 &mmv MOVE_Y(-ZMK_POINTING_FAST_MOVE_VAL)  &mkp RCLK                                &trans  &trans
&trans  &trans  &trans  &trans  &trans  &trans                    &msc SCRL_DOWN  &mmv MOVE_X(-ZMK_POINTING_FAST_MOVE_VAL)  &mmv MOVE_Y(ZMK_POINTING_FAST_MOVE_VAL)   &mmv MOVE_X(ZMK_POINTING_FAST_MOVE_VAL)  &trans  &trans
&trans  &trans  &trans  &trans  &trans  &trans  &trans    &trans  &kp PAGE_DOWN   &trans                                    &trans                                    &trans                                   &trans  &trans
                &trans  &trans  &trans  &trans  &trans    &trans  &mkp LCLK       &trans                                    &trans                                    &trans
            >;
        };

        layers {
            bindings = <
&to MAC_BASE_LAYER  &to LINUX_LAYER     &to SYMBOLS_LAYER  &to NAVIGATION_LAYER_MAC  &to NAVIGATION_LAYER_LINUX  &to CONNECTIVITY_LAYER                    &to APP_ACTIONS_LAYER     &to MAC_BASE_LAYER  &to FN_AND_NUMBERS_LAYER  &to POINTER_LAYER  &none  &none
&none               &none               &none              &none                     &none                       &none                                     &none                     &none               &none                     &none              &none  &none
&none               &none               &none              &none                     &to FN_AND_NUMBERS_LAYER    &none                                     &none                     &none               &none                     &to LINUX_LAYER    &none  &none
&none               &to MAC_BASE_LAYER  &none              &none                     &none                       &none                   &trans    &trans  &to FN_AND_NUMBERS_LAYER  &to MAC_BASE_LAYER  &none                     &none              &none  &none
                                        &none              &none                     &none                       &trans                  &trans    &trans  &trans                    &none               &none                     &none
            >;
        };

        undo_mac {
            bindings = <
&trans  &trans  &trans  &trans  &trans  &trans                    &trans  &trans     &trans  &trans         &trans  &trans
&trans  &trans  &trans  &trans  &trans  &trans                    &trans  &trans     &trans  &trans         &trans  &trans
&trans  &trans  &trans  &trans  &trans  &trans                    &trans  &kp LG(Z)  &trans  &kp LG(LS(Z))  &trans  &trans
&trans  &trans  &trans  &trans  &trans  &trans  &trans    &trans  &trans  &trans     &trans  &trans         &trans  &trans
                &trans  &trans  &trans  &trans  &trans    &trans  &none   &trans     &trans  &trans
            >;

            sensor-bindings = <&inc_dec_kp A B>, <&inc_dec_kp LG(Z) LG(LS(Z))>;
        };

        macros {
            bindings = <
&trans  &trans  &trans  &trans  &dm_play_stop                 &dm_record_stop_with_confirmation                    &trans  &trans  &trans  &trans                             &trans  &dm_reset
&trans  &trans  &trans  &trans  &dm_play_with_confirmation 1  &dm_record_with_confirmation 1                       &trans  &trans  &trans  &trans                             &trans  &trans
&trans  &trans  &trans  &trans  &dm_play_with_confirmation 2  &dm_record_with_confirmation 2                       &trans  &trans  &trans  &dm_play_loop_with_confirmation 1  &trans  &trans
&trans  &trans  &trans  &trans  &dm_play_with_confirmation 3  &dm_record_with_confirmation 3     &trans    &trans  &trans  &trans  &trans  &trans                             &trans  &trans
                &trans  &trans  &trans                        &trans                             &trans    &trans  &trans  &trans  &trans  &trans
            >;
        };

        app_switch_lnx {
            bindings = <
&app_switch_cancel  &trans  &trans  &trans       &trans   &trans                                 &trans  &trans  &trans  &trans  &trans  &app_switch_cancel
&trans              &trans  &trans  &trans       &trans   &trans                                 &trans  &trans  &trans  &trans  &trans  &trans
&trans              &trans  &trans  &kp LS(TAB)  &kp TAB  &app_switch_confirm                    &trans  &trans  &trans  &trans  &trans  &trans
&trans              &trans  &trans  &trans       &trans   &trans               &trans    &trans  &trans  &trans  &trans  &trans  &trans  &app_switch_confirm
                            &trans  &trans       &trans   &trans               &trans    &trans  &trans  &trans
            >;
        };

        window_switch_lnx {
            bindings = <
&window_switch_cancel  &trans  &trans  &trans         &trans     &trans                                    &trans  &trans  &trans  &trans  &trans  &window_switch_cancel
&trans                 &trans  &trans  &kp LS(GRAVE)  &kp GRAVE  &window_switch_confirm                    &trans  &trans  &trans  &trans  &trans  &trans
&trans                 &trans  &trans  &trans         &trans     &trans                                    &trans  &trans  &trans  &trans  &trans  &trans
&trans                 &trans  &trans  &trans         &trans     &trans                  &trans    &trans  &trans  &trans  &trans  &trans  &trans  &window_switch_confirm
                               &trans  &trans         &trans     &none                   &trans    &trans  &trans  &trans
            >;
        };

        app_switch_mac {
            bindings = <
&app_switch_cancel  &trans  &trans  &trans       &trans   &trans                                 &trans  &trans  &trans  &trans  &trans  &app_switch_cancel
&trans              &trans  &trans  &trans       &trans   &trans                                 &trans  &trans  &trans  &trans  &trans  &trans
&trans              &trans  &trans  &kp LS(TAB)  &kp TAB  &app_switch_confirm                    &trans  &trans  &trans  &trans  &trans  &trans
&trans              &trans  &trans  &trans       &trans   &trans               &trans    &trans  &trans  &trans  &trans  &trans  &trans  &app_switch_confirm
                            &trans  &trans       &trans   &none                &trans    &trans  &trans  &trans
            >;
        };

        window_switch_mac {
            bindings = <
&window_switch_cancel  &trans  &trans  &trans         &trans     &trans                                    &trans  &trans  &trans  &trans  &trans  &window_switch_cancel
&trans                 &trans  &trans  &trans         &trans     &trans                                    &trans  &trans  &trans  &trans  &trans  &trans
&trans                 &trans  &trans  &kp LS(GRAVE)  &kp GRAVE  &window_switch_confirm                    &trans  &trans  &trans  &trans  &trans  &trans
&trans                 &trans  &trans  &trans         &trans     &trans                  &trans    &trans  &trans  &trans  &trans  &trans  &trans  &window_switch_confirm
                               &trans  &trans         &trans     &none                   &trans    &trans  &trans  &trans
            >;
        };
    };

    conditional_layers {
        compatible = "zmk,conditional-layers";

        to_layers_layer {
            if-layers = <CONNECTIVITY_LAYER POINTER_LAYER>;
            then-layer = <LAYERS_LAYER>;
        };
    };
};
